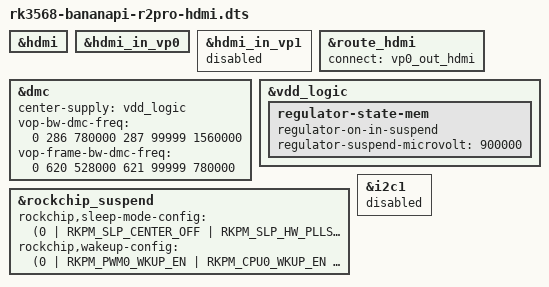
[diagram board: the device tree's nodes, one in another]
// SPDX-License-Identifier: (GPL-2.0+ OR MIT)
/*
 * Copyright (c) 2020 Rockchip Electronics Co., Ltd.
 *
 */

/dts-v1/;

#include <dt-bindings/gpio/gpio.h>
#include <dt-bindings/pinctrl/rockchip.h>
#include "rk3568-bananapi-r2pro.dts"

&hdmi {
	status = "okay";
};

&hdmi_in_vp0 {
	status = "okay";
};

&hdmi_in_vp1 {
	status = "disabled";
};

&route_hdmi {
	status = "okay";
	connect = <&vp0_out_hdmi>;
};

&dmc {
	center-supply = <&vdd_logic>;
	vop-bw-dmc-freq = <
	/* min_bw(MB/s) max_bw(MB/s) freq(KHz) */
		0       286     780000
		287     99999   1560000
	>;
	vop-frame-bw-dmc-freq = <
	/* min_bw(MB/s) max_bw(MB/s) freq(KHz) */
		0       620     528000
		621     99999   780000
	>;
	status = "okay";
};

&vdd_logic {
	regulator-state-mem {
		regulator-on-in-suspend;
		regulator-suspend-microvolt = <900000>;
	};
};

&rockchip_suspend {
	status = "okay";
	//rockchip,virtual-poweroff = <1>;
	rockchip,sleep-mode-config = <
		(0
		| RKPM_SLP_CENTER_OFF
		| RKPM_SLP_HW_PLLS_OFF
		| RKPM_SLP_PMUALIVE_32K
		| RKPM_SLP_PMIC_LP
		| RKPM_SLP_32K_PVTM
		)
	>;
	rockchip,wakeup-config = <
		(0
		| RKPM_PWM0_WKUP_EN
		| RKPM_CPU0_WKUP_EN
		| RKPM_GPIO_WKUP_EN
		)
	>;
};

&i2c1 {
	status = "disabled";
};
